# HDSC_HC32F165 register map
Vendor: HDSC; Series: ARMCM0P; File version: 1.0
CPU: CM0P r0p1, little endian, MPU, FPU, 4 interrupt priority bits
Registers are 32-bit, read-write, reset 0x0 unless marked. A register's access mark holds for its fields unless they carry their own. Offsets are from the block's base; [hi:lo] are bit positions; {n}, {i} and the like mark numbered series.

## LED
Base 0x40010C00
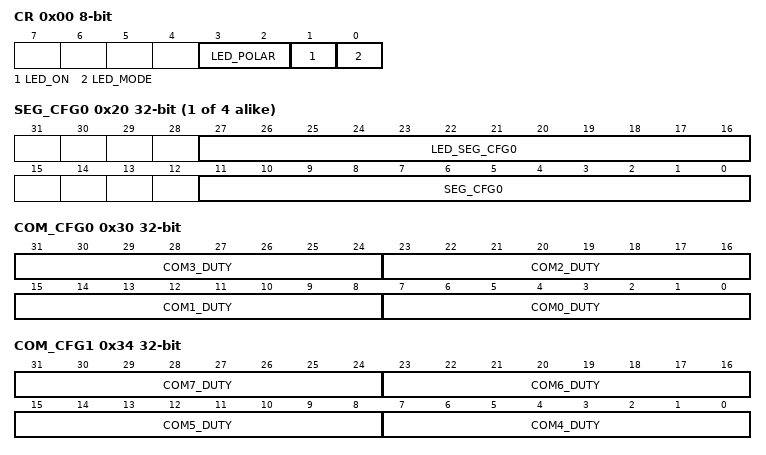
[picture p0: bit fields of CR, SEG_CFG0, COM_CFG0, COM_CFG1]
0x00 CR 8-bit
  [3:2] LED_POLAR, [1] LED_ON, [0] LED_MODE
0x04 DISCOM 8-bit
0x08 DZ 8-bit
0x0C COM_EN 8-bit
0x10 SEG_EN 16-bit
  [11:0] SEG_EN
0x14 INT 8-bit
  [0] LED_INT
0x18 INT_MASK 8-bit
  [0] LED_INT_MASK
0x1C INT_CLR 8-bit
  [0] LED_INT_CLR
{0x20+4i} SEG_CFG{i} (i=0..3)
  [27:16] LED_SEG_CFG{i}, [11:0] SEG_CFG{i}
0x30 COM_CFG0
  [8n+7:8n] COM{n}_DUTY (n=0..3)
0x34 COM_CFG1
  [8n-25:8n-32] COM{n}_DUTY (n=4..7)

## MAU
Base 0x40054800
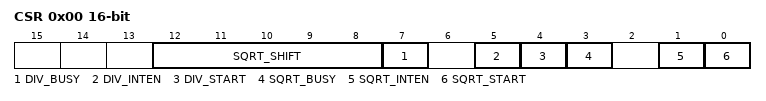
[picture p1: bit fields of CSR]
0x00 CSR 16-bit
  [12:8] SQRT_SHIFT, [7] DIV_BUSY, [5] DIV_INTEN, [4] DIV_START, [3] SQRT_BUSY, [1] SQRT_INTEN, [0] SQRT_START
0x04 DTR0
0x10 DTR1
0x14 DTR2
0x18 RTR1

## PWC
Base 0x40054000
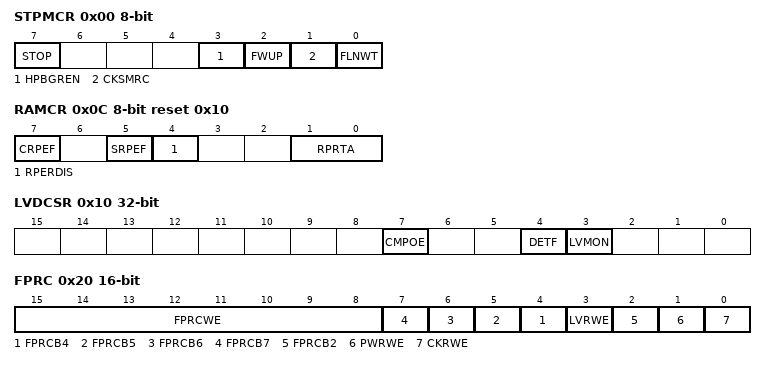
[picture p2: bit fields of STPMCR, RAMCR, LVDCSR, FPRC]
0x00 STPMCR 8-bit
  [7] STOP, [3] HPBGREN, [2] FWUP, [1] CKSMRC, [0] FLNWT
0x08 PWRMON 8-bit
  [0] TS
0x0C RAMCR 8-bit reset 0x10
  [7] CRPEF, [5] SRPEF, [4] RPERDIS, [1:0] RPRTA
0x10 LVDCSR ro
  [7] CMPOE rw, [4] DETF rw, [3] LVMON
0x20 FPRC 16-bit
  [15:8] FPRCWE wo, [n] FPRCB{n} (n=4..7), [3] LVRWE, [2] FPRCB2, [1] PWRWE, [0] CKRWE
0x40 DBGC 8-bit
  [0] DBGEN
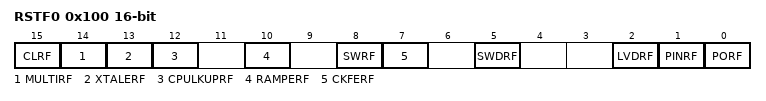
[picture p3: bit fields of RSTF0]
0x100 RSTF0 16-bit
  [15] CLRF, [14] MULTIRF, [13] XTALERF, [12] CPULKUPRF, [10] RAMPERF, [8] SWRF, [7] CKFERF, [5] SWDRF, [2] LVDRF, [1] PINRF, [0] PORF

## RMU
Base 0x40054100
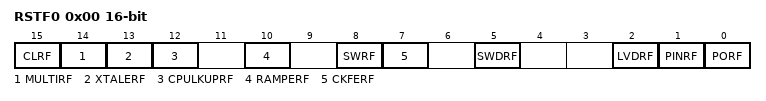
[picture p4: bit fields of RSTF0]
0x00 RSTF0 16-bit
  [15] CLRF, [14] MULTIRF, [13] XTALERF, [12] CPULKUPRF, [10] RAMPERF, [8] SWRF, [7] CKFERF, [5] SWDRF, [2] LVDRF, [1] PINRF, [0] PORF

## RTC
Base 0x4004C000
0x00 CR0 8-bit
  [0] RESET
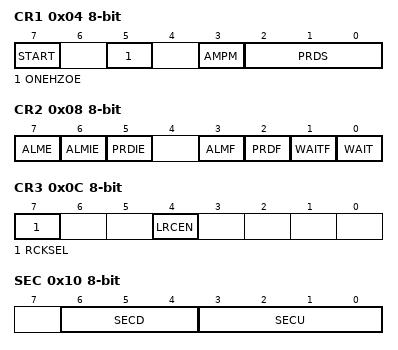
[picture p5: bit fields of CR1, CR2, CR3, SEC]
0x04 CR1 8-bit
  [7] START, [5] ONEHZOE, [3] AMPM, [2:0] PRDS
0x08 CR2 8-bit
  [7] ALME, [6] ALMIE, [5] PRDIE, [3] ALMF, [2] PRDF, [1] WAITF, [0] WAIT
0x0C CR3 8-bit
  [7] RCKSEL, [4] LRCEN
0x10 SEC 8-bit
  [6:4] SECD, [3:0] SECU
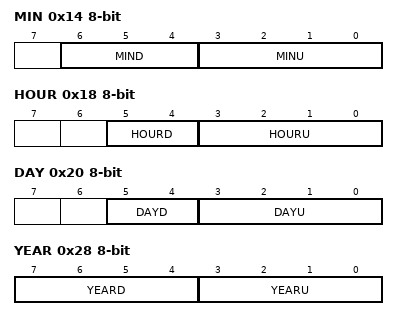
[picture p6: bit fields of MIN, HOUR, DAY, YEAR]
0x14 MIN 8-bit
  [6:4] MIND, [3:0] MINU
0x18 HOUR 8-bit
  [5:4] HOURD, [3:0] HOURU
0x1C WEEK 8-bit
  [2:0] WEEK
0x20 DAY 8-bit
  [5:4] DAYD, [3:0] DAYU
0x24 MON 8-bit
  [4:0] MON
0x28 YEAR 8-bit
  [7:4] YEARD, [3:0] YEARU
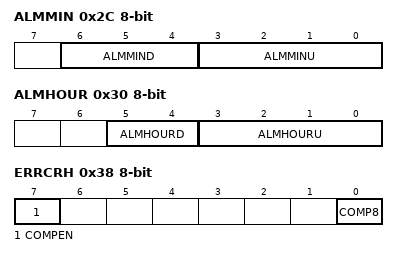
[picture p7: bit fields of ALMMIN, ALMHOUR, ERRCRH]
0x2C ALMMIN 8-bit
  [6:4] ALMMIND, [3:0] ALMMINU
0x30 ALMHOUR 8-bit
  [5:4] ALMHOURD, [3:0] ALMHOURU
0x34 ALMWEEK 8-bit
  [6:0] ALMWEEK
0x38 ERRCRH 8-bit
  [7] COMPEN, [0] COMP8
0x3C ERRCRL 8-bit reset 0x20

## SPI1 — desc SPI
Base 0x4001C000
Same registers: SPI2 0x4001C400
0x00 DR
  [15:0] SPD
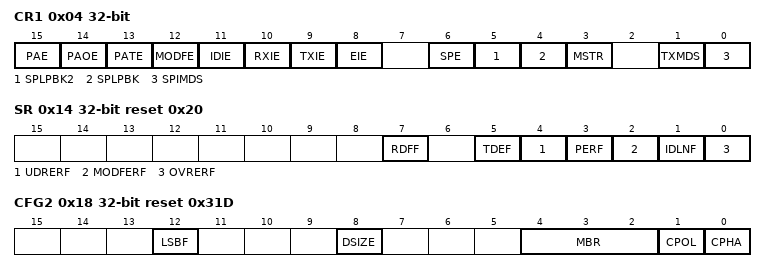
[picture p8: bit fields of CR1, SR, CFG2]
0x04 CR1
  [15] PAE, [14] PAOE, [13] PATE, [12] MODFE, [11] IDIE, [10] RXIE, [9] TXIE, [8] EIE, [6] SPE, [5] SPLPBK2, [4] SPLPBK, [3] MSTR, [1] TXMDS, [0] SPIMDS
0x0C CFG1 reset 0x10
  [8] SS0PV
0x14 SR reset 0x20
  [7] RDFF, [5] TDEF, [4] UDRERF, [3] PERF, [2] MODFERF, [1] IDLNF ro, [0] OVRERF
0x18 CFG2 reset 0x31D
  [12] LSBF, [8] DSIZE, [4:2] MBR, [1] CPOL, [0] CPHA

## SWDT
Base 0x40049400
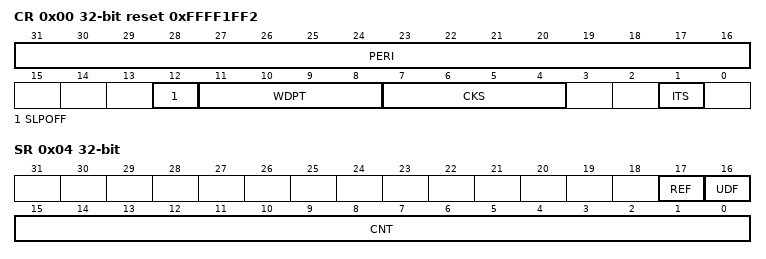
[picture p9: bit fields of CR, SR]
0x00 CR reset 0xFFFF1FF2
  [31:16] PERI, [12] SLPOFF, [11:8] WDPT, [7:4] CKS, [1] ITS
0x04 SR
  [17] REF, [16] UDF, [15:0] CNT ro
0x08 RR
  [15:0] RF

## TK
Base 0x4001BC00
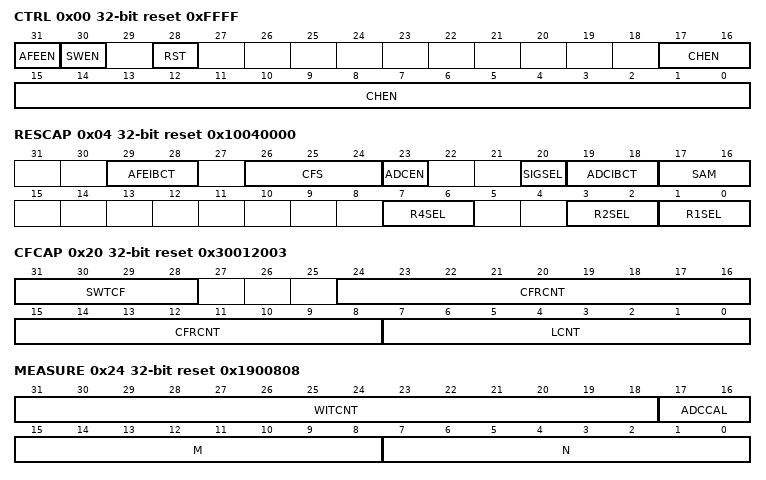
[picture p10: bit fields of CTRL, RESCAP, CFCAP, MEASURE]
0x00 CTRL reset 0xFFFF
  [31] AFEEN, [30] SWEN, [28] RST, [17:0] CHEN
0x04 RESCAP reset 0x10040000
  [29:28] AFEIBCT, [26:24] CFS, [23] ADCEN, [20] SIGSEL, [19:18] ADCIBCT, [17:16] SAM, [7:6] R4SEL, [3:2] R2SEL, [1:0] R1SEL
{0x4+4i} SWTCNT{i} reset 0x64 (i=1..6)
  [15:0] HCNT
0x20 CFCAP reset 0x30012003
  [31:28] SWTCF, [24:8] CFRCNT, [7:0] LCNT
0x24 MEASURE reset 0x1900808
  [31:18] WITCNT, [17:16] ADCCAL, [15:8] M, [7:0] N
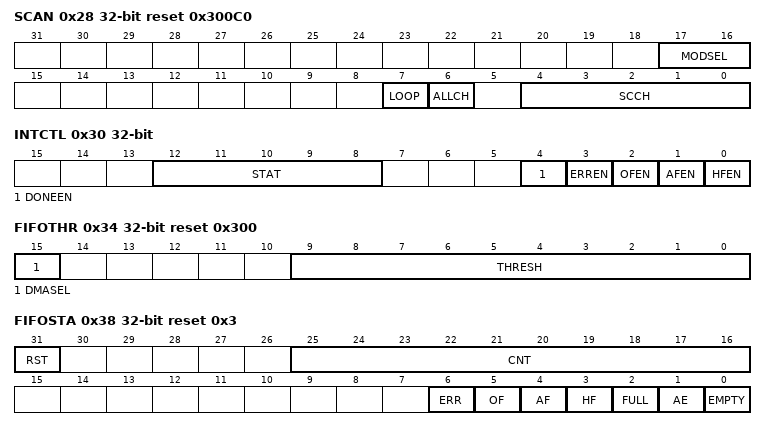
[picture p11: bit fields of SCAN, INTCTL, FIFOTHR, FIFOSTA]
0x28 SCAN reset 0x300C0
  [17:16] MODSEL, [7] LOOP, [6] ALLCH, [4:0] SCCH
0x2C START
  [0] START
0x30 INTCTL
  [12:8] STAT, [4] DONEEN, [3] ERREN, [2] OFEN, [1] AFEN, [0] HFEN
0x34 FIFOTHR reset 0x300
  [15] DMASEL, [9:0] THRESH
0x38 FIFOSTA ro reset 0x3
  [31] RST wo, [25:16] CNT, [6] ERR, [5] OF, [4] AF, [3] HF, [2] FULL, [1] AE, [0] EMPTY
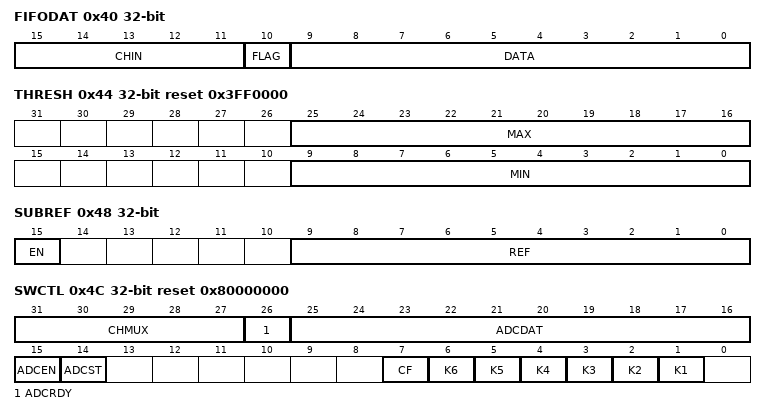
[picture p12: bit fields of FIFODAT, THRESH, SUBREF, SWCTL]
0x40 FIFODAT
  [15:11] CHIN, [10] FLAG, [9:0] DATA
0x44 THRESH reset 0x3FF0000
  [25:16] MAX, [9:0] MIN
0x48 SUBREF
  [15] EN, [9:0] REF
0x4C SWCTL reset 0x80000000
  [31:27] CHMUX, [26] ADCRDY ro, [25:16] ADCDAT ro, [15] ADCEN, [14] ADCST, [7] CF, [n] K{n} (n=1..6)
{0x50+4i} FIXCH{i} (i=0..9)
  [5:0] CAPCPS
0x78 FIXCHA
  [5:0] CAPCPS
0x7C FIXCHB
  [5:0] CAPCPS
0x80 FIXCHC
  [5:0] CAPCPS
0x84 FIXCHD
  [5:0] CAPCPS
0x88 FIXCHE
  [5:0] CAPCPS
0x8C FIXCHF
  [5:0] CAPCPS
0x90 FIXCH10
  [5:0] CAPCPS
0x94 FIXCH11
  [5:0] CAPCPS
